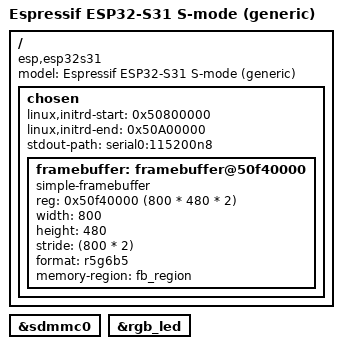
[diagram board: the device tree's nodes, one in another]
// SPDX-License-Identifier: GPL-2.0+
/*
 * ESP32-S31 Device Tree Source
 * Author: Marco Müller <hello@annoyedmilk.ch>
 */
/dts-v1/;
#include "esp32s31.dtsi"

/ {
	model = "Espressif ESP32-S31 S-mode (generic)";
	compatible = "esp,esp32s31";

	chosen {
		linux,initrd-start = <0x50800000>;
		linux,initrd-end = <0x50A00000>;
		stdout-path = "serial0:115200n8";

		/*
		 * The loader starts the 800x480 RGB panel of the Korvo-1.  The
		 * LCD_CAM DMA then reads an RGB565 buffer at the top of PSRAM,
		 * so Linux only describes it.  fb_region reserves the memory.
		 * of_platform makes this device for a simple-framebuffer under
		 * /chosen.  If the loader gives GPIO33/34 to USB Serial/JTAG,
		 * it does not start the display: fb0 exists but shows nothing.
		 */
		framebuffer: framebuffer@50f40000 {
			compatible = "simple-framebuffer";
			reg = <0x50f40000 (800 * 480 * 2)>;
			width = <800>;
			height = <480>;
			stride = <(800 * 2)>;
			format = "r5g6b5";
			memory-region = <&fb_region>;
		};
	};
};

&sdmmc0 { status = "okay"; };

/* WS2812 RGB LED on GPIO37. */
&rgb_led { status = "okay"; };
